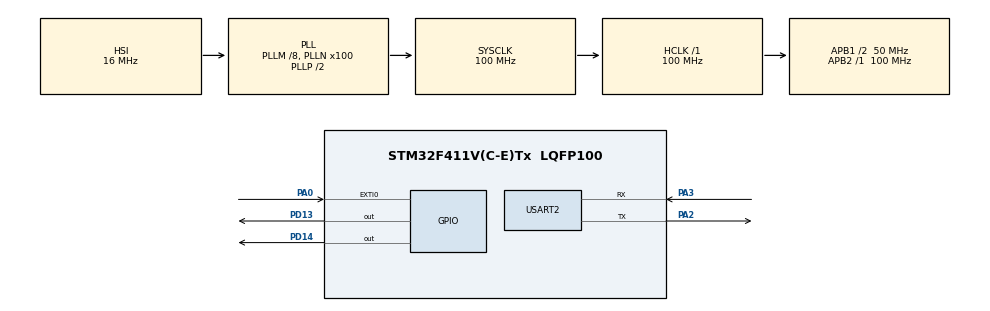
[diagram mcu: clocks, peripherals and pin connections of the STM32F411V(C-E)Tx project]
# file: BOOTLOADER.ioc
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Mcu.Family=STM32F4
Mcu.Name=STM32F411V(C-E)Tx
Mcu.Package=LQFP100
NVIC.EXTI0_IRQn=true\:2\:0\:true\:false\:true\:true\:true\:true
NVIC.PriorityGroup=NVIC_PRIORITYGROUP_4
PA0-WKUP.Signal=GPXTI0
PA13.Mode=Serial_Wire
PA13.Signal=SYS_JTMS-SWDIO
PA14.Mode=Serial_Wire
PA14.Signal=SYS_JTCK-SWCLK
PA2.Mode=Asynchronous
PA2.Signal=USART2_TX
PA3.Mode=Asynchronous
PA3.Signal=USART2_RX
PD13.Signal=GPIO_Output
PD14.Signal=GPIO_Output
PH0\ -\ OSC_IN.Mode=HSE-External-Oscillator
PH0\ -\ OSC_IN.Signal=RCC_OSC_IN
PH1\ -\ OSC_OUT.Mode=HSE-External-Oscillator
PH1\ -\ OSC_OUT.Signal=RCC_OSC_OUT
ProjectManager.HeapSize=0x200
ProjectManager.StackSize=0x400
ProjectManager.TargetToolchain=STM32CubeIDE
RCC.48MHZClocksFreq_Value=50000000
RCC.AHBFreq_Value=100000000
RCC.APB1CLKDivider=RCC_HCLK_DIV2
RCC.APB1Freq_Value=50000000
RCC.APB1TimFreq_Value=100000000
RCC.APB2Freq_Value=100000000
RCC.APB2TimFreq_Value=100000000
RCC.CortexFreq_Value=100000000
RCC.HCLKFreq_Value=100000000
RCC.HSE_VALUE=25000000
RCC.HSI_VALUE=16000000
RCC.LSE_VALUE=32768
RCC.PLLM=8
RCC.PLLN=100
RCC.SYSCLKFreq_VALUE=100000000
RCC.SYSCLKSource=RCC_SYSCLKSOURCE_PLLCLK
RCC.VCOOutputFreq_Value=200000000
USART2.VirtualMode=VM_ASYNC
board=custom

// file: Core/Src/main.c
/* USER CODE BEGIN Header */
/**
  ******************************************************************************
  * @file           : main.c
  * @brief          : Main program body
  ******************************************************************************
  * @attention
  *
  * Copyright (c) 2026 STMicroelectronics.
  * All rights reserved.
  *
  * This software is licensed under terms that can be found in the LICENSE file
  * in the root directory of this software component.
  * If no LICENSE file comes with this software, it is provided AS-IS.
  *
  ******************************************************************************
  */
/* USER CODE END Header */
#include "main.h"

/* USER CODE BEGIN Includes */
#include "bootloader.h"
/* USER CODE END Includes */

UART_HandleTypeDef huart2;

/* USER CODE BEGIN PV */
int a = 0;
/* USER CODE END PV */

void SystemClock_Config(void);
static void MX_GPIO_Init(void);
static void MX_USART2_UART_Init(void);

int main(void)
{

  /* MCU Configuration--------------------------------------------------------*/

  /* Reset of all peripherals, Initializes the Flash interface and the Systick. */
  HAL_Init();

  /* Configure the system clock */
  SystemClock_Config();

  /* Initialize all configured peripherals */
  MX_GPIO_Init();
  MX_USART2_UART_Init();
  /* USER CODE BEGIN 2 */
  GPIO_PinState btn_state = HAL_GPIO_ReadPin(GPIOA, GPIO_PIN_0);
  if ((btn_state == GPIO_PIN_SET) ||
        (Bootloader_IsOTARequested() == 1U) ||
        (Bootloader_IsAppValid() == 0U))
    {
        Bootloader_ReceiveAndFlash(&huart2);
    }
    else
    {
        /* Nếu không có yêu cầu OTA và App hợp lệ -> Nhảy thẳng sang App */
        Bootloader_JumpToApp();
    }
  /* USER CODE END 2 */

  /* Infinite loop */
  while (1)
  {

    /* USER CODE BEGIN 3 */
	  HAL_GPIO_TogglePin(GPIOD, GPIO_PIN_14);
	  HAL_Delay(300U);
  }
  /* USER CODE END 3 */
}

void SystemClock_Config(void)
{
  RCC_OscInitTypeDef RCC_OscInitStruct = {0};
  RCC_ClkInitTypeDef RCC_ClkInitStruct = {0};

  /** Configure the main internal regulator output voltage
  */
  __HAL_RCC_PWR_CLK_ENABLE();
  __HAL_PWR_VOLTAGESCALING_CONFIG(PWR_REGULATOR_VOLTAGE_SCALE1);

  /** Initializes the RCC Oscillators according to the specified parameters
  * in the RCC_OscInitTypeDef structure.
  */
  RCC_OscInitStruct.OscillatorType = RCC_OSCILLATORTYPE_HSI;
  RCC_OscInitStruct.HSIState = RCC_HSI_ON;
  RCC_OscInitStruct.HSICalibrationValue = RCC_HSICALIBRATION_DEFAULT;
  RCC_OscInitStruct.PLL.PLLState = RCC_PLL_ON;
  RCC_OscInitStruct.PLL.PLLSource = RCC_PLLSOURCE_HSI;
  RCC_OscInitStruct.PLL.PLLM = 8;
  RCC_OscInitStruct.PLL.PLLN = 100;
  RCC_OscInitStruct.PLL.PLLP = RCC_PLLP_DIV2;
  RCC_OscInitStruct.PLL.PLLQ = 4;
  if (HAL_RCC_OscConfig(&RCC_OscInitStruct) != HAL_OK)
  {
    Error_Handler();
  }

  /** Initializes the CPU, AHB and APB buses clocks
  */
  RCC_ClkInitStruct.ClockType = RCC_CLOCKTYPE_HCLK|RCC_CLOCKTYPE_SYSCLK
                              |RCC_CLOCKTYPE_PCLK1|RCC_CLOCKTYPE_PCLK2;
  RCC_ClkInitStruct.SYSCLKSource = RCC_SYSCLKSOURCE_PLLCLK;
  RCC_ClkInitStruct.AHBCLKDivider = RCC_SYSCLK_DIV1;
  RCC_ClkInitStruct.APB1CLKDivider = RCC_HCLK_DIV2;
  RCC_ClkInitStruct.APB2CLKDivider = RCC_HCLK_DIV1;

  if (HAL_RCC_ClockConfig(&RCC_ClkInitStruct, FLASH_LATENCY_3) != HAL_OK)
  {
    Error_Handler();
  }
}

static void MX_USART2_UART_Init(void)
{

  huart2.Instance = USART2;
  huart2.Init.BaudRate = 115200;
  huart2.Init.WordLength = UART_WORDLENGTH_8B;
  huart2.Init.StopBits = UART_STOPBITS_1;
  huart2.Init.Parity = UART_PARITY_NONE;
  huart2.Init.Mode = UART_MODE_TX_RX;
  huart2.Init.HwFlowCtl = UART_HWCONTROL_NONE;
  huart2.Init.OverSampling = UART_OVERSAMPLING_16;
  if (HAL_UART_Init(&huart2) != HAL_OK)
  {
    Error_Handler();
  }

}

static void MX_GPIO_Init(void)
{
  GPIO_InitTypeDef GPIO_InitStruct = {0};

  /* GPIO Ports Clock Enable */
  __HAL_RCC_GPIOH_CLK_ENABLE();
  __HAL_RCC_GPIOA_CLK_ENABLE();
  __HAL_RCC_GPIOD_CLK_ENABLE();

  /*Configure GPIO pin Output Level */
  HAL_GPIO_WritePin(GPIOD, GPIO_PIN_13|GPIO_PIN_14, GPIO_PIN_RESET);

  /*Configure GPIO pin : PA0 */
  GPIO_InitStruct.Pin = GPIO_PIN_0;
  GPIO_InitStruct.Mode = GPIO_MODE_IT_RISING;
  GPIO_InitStruct.Pull = GPIO_NOPULL;
  HAL_GPIO_Init(GPIOA, &GPIO_InitStruct);

  /*Configure GPIO pins : PD13 PD14 */
  GPIO_InitStruct.Pin = GPIO_PIN_13|GPIO_PIN_14;
  GPIO_InitStruct.Mode = GPIO_MODE_OUTPUT_PP;
  GPIO_InitStruct.Pull = GPIO_NOPULL;
  GPIO_InitStruct.Speed = GPIO_SPEED_FREQ_LOW;
  HAL_GPIO_Init(GPIOD, &GPIO_InitStruct);

  /* EXTI interrupt init*/
  HAL_NVIC_SetPriority(EXTI0_IRQn, 2, 0);
  HAL_NVIC_EnableIRQ(EXTI0_IRQn);

}

void Error_Handler(void)
{
  __disable_irq();
  while (1)
  {
  }
}
